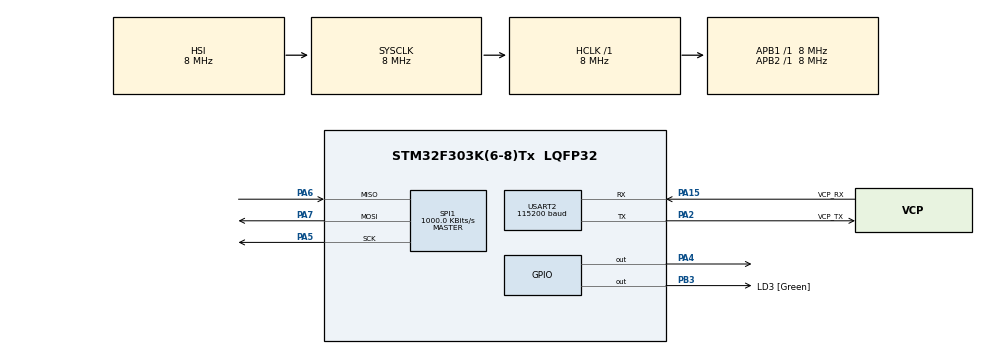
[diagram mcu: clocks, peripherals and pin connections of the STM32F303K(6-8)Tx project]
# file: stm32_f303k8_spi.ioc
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Mcu.Family=STM32F3
Mcu.Name=STM32F303K(6-8)Tx
Mcu.Package=LQFP32
NVIC.PriorityGroup=NVIC_PRIORITYGROUP_4
PA13.GPIO_Label=SWDIO
PA13.Mode=Serial_Wire
PA13.Signal=SYS_JTMS-SWDIO
PA14.GPIO_Label=SWCLK
PA14.Mode=Serial_Wire
PA14.Signal=SYS_JTCK-SWCLK
PA15.GPIO_Label=VCP_RX
PA15.Mode=Asynchronous
PA15.Signal=USART2_RX
PA2.GPIO_Label=VCP_TX
PA2.Mode=Asynchronous
PA2.Signal=USART2_TX
PA4.GPIO_PuPd=GPIO_NOPULL
PA4.Signal=GPIO_Output
PA5.GPIO_PuPd=GPIO_PULLUP
PA5.Mode=Full_Duplex_Master
PA5.Signal=SPI1_SCK
PA6.GPIO_PuPd=GPIO_PULLUP
PA6.Mode=Full_Duplex_Master
PA6.Signal=SPI1_MISO
PA7.GPIO_PuPd=GPIO_PULLUP
PA7.Mode=Full_Duplex_Master
PA7.Signal=SPI1_MOSI
PB3.GPIO_Label=LD3 [Green]
PB3.Signal=GPIO_Output
PF0\ /\ OSC_IN.GPIO_Label=MCO
PF0\ /\ OSC_IN.Mode=HSE-External-Clock-Source
PF0\ /\ OSC_IN.Signal=RCC_OSC_IN
ProjectManager.HeapSize=0x200
ProjectManager.StackSize=0x400
ProjectManager.TargetToolchain=STM32CubeIDE
RCC.AHBFreq_Value=8000000
RCC.APB1Freq_Value=8000000
RCC.APB1TimFreq_Value=8000000
RCC.APB2Freq_Value=8000000
RCC.APB2TimFreq_Value=8000000
RCC.CortexFreq_Value=8000000
RCC.HCLKFreq_Value=8000000
RCC.HSE_VALUE=8000000
RCC.HSI_VALUE=8000000
RCC.PLLMUL=RCC_PLL_MUL9
RCC.SYSCLKFreq_VALUE=8000000
SPI1.BaudRatePrescaler=SPI_BAUDRATEPRESCALER_8
SPI1.CLKPhase=SPI_PHASE_2EDGE
SPI1.CRCCalculation=SPI_CRCCALCULATION_DISABLE
SPI1.CalculateBaudRate=1000.0 KBits/s
SPI1.DataSize=SPI_DATASIZE_8BIT
SPI1.Direction=SPI_DIRECTION_2LINES
SPI1.Mode=SPI_MODE_MASTER
SPI1.VirtualType=VM_MASTER
USART2.BaudRate=115200
USART2.VirtualMode-Asynchronous=VM_ASYNC
board=NUCLEO-F303K8

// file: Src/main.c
/* USER CODE BEGIN Header */
/**
  ******************************************************************************
  * @file           : main.c
  * @brief          : Main program body
  ******************************************************************************
  * @attention
  *
  * <h2><center>&copy; Copyright (c) 2019 STMicroelectronics.
  * All rights reserved.</center></h2>
  *
  * This software component is licensed by ST under BSD 3-Clause license,
  * the "License"; You may not use this file except in compliance with the
  * License. You may obtain a copy of the License at:
  *                        opensource.org/licenses/BSD-3-Clause
  *
  ******************************************************************************
  */
/* USER CODE END Header */

#include "main.h"

SPI_HandleTypeDef hspi1;

UART_HandleTypeDef huart2;

void SystemClock_Config(void);
static void MX_GPIO_Init(void);
static void MX_USART2_UART_Init(void);
static void MX_SPI1_Init(void);

int main(void)
{

  /* MCU Configuration--------------------------------------------------------*/

  /* Reset of all peripherals, Initializes the Flash interface and the Systick. */
  HAL_Init();

  /* Configure the system clock */
  SystemClock_Config();

  /* Initialize all configured peripherals */
  MX_GPIO_Init();
  MX_USART2_UART_Init();
  MX_SPI1_Init();
  /* USER CODE BEGIN 2 */
  uint8_t aTxBuffer[]={"ababababab"};
  aTxBuffer[0]=0xA;
  uint8_t aTxBuffer2[]={"jajajajaja"};
  uint8_t aRxBuffer[11]={0};
  uint8_t aRxBuffer2[11]={0};
  HAL_GPIO_WritePin(GPIOA,GPIO_PIN_4,1);
  /* USER CODE END 2 */

  /* Infinite loop */
  while (1)
  {

    /* USER CODE BEGIN 3 */
	HAL_GPIO_WritePin(GPIOA,GPIO_PIN_4,0);
	for(int i = 0; i < 11; i++){

		HAL_SPI_TransmitReceive(&hspi1,(uint8_t*)&aTxBuffer[i],(uint8_t*)&aRxBuffer[i],1,0xFFFFFFFF);

	}
	HAL_GPIO_WritePin(GPIOA,GPIO_PIN_4,1);
	HAL_UART_Transmit(&huart2,aRxBuffer,11,0xFF);
	HAL_Delay(100);

  }
  /* USER CODE END 3 */
}

void SystemClock_Config(void)
{
  RCC_OscInitTypeDef RCC_OscInitStruct = {0};
  RCC_ClkInitTypeDef RCC_ClkInitStruct = {0};

  /** Initializes the CPU, AHB and APB busses clocks
  */
  RCC_OscInitStruct.OscillatorType = RCC_OSCILLATORTYPE_HSI;
  RCC_OscInitStruct.HSIState = RCC_HSI_ON;
  RCC_OscInitStruct.HSICalibrationValue = RCC_HSICALIBRATION_DEFAULT;
  RCC_OscInitStruct.PLL.PLLState = RCC_PLL_NONE;
  if (HAL_RCC_OscConfig(&RCC_OscInitStruct) != HAL_OK)
  {
    Error_Handler();
  }
  /** Initializes the CPU, AHB and APB busses clocks
  */
  RCC_ClkInitStruct.ClockType = RCC_CLOCKTYPE_HCLK|RCC_CLOCKTYPE_SYSCLK
                              |RCC_CLOCKTYPE_PCLK1|RCC_CLOCKTYPE_PCLK2;
  RCC_ClkInitStruct.SYSCLKSource = RCC_SYSCLKSOURCE_HSI;
  RCC_ClkInitStruct.AHBCLKDivider = RCC_SYSCLK_DIV1;
  RCC_ClkInitStruct.APB1CLKDivider = RCC_HCLK_DIV1;
  RCC_ClkInitStruct.APB2CLKDivider = RCC_HCLK_DIV1;

  if (HAL_RCC_ClockConfig(&RCC_ClkInitStruct, FLASH_LATENCY_0) != HAL_OK)
  {
    Error_Handler();
  }
}

static void MX_SPI1_Init(void)
{

  /* SPI1 parameter configuration*/
  hspi1.Instance = SPI1;
  hspi1.Init.Mode = SPI_MODE_MASTER;
  hspi1.Init.Direction = SPI_DIRECTION_2LINES;
  hspi1.Init.DataSize = SPI_DATASIZE_8BIT;
  hspi1.Init.CLKPolarity = SPI_POLARITY_LOW;
  hspi1.Init.CLKPhase = SPI_PHASE_2EDGE;
  hspi1.Init.NSS = SPI_NSS_SOFT;
  hspi1.Init.BaudRatePrescaler = SPI_BAUDRATEPRESCALER_8;
  hspi1.Init.FirstBit = SPI_FIRSTBIT_MSB;
  hspi1.Init.TIMode = SPI_TIMODE_DISABLE;
  hspi1.Init.CRCCalculation = SPI_CRCCALCULATION_DISABLE;
  hspi1.Init.CRCPolynomial = 7;
  hspi1.Init.CRCLength = SPI_CRC_LENGTH_DATASIZE;
  hspi1.Init.NSSPMode = SPI_NSS_PULSE_DISABLE;
  if (HAL_SPI_Init(&hspi1) != HAL_OK)
  {
    Error_Handler();
  }

}

static void MX_USART2_UART_Init(void)
{

  huart2.Instance = USART2;
  huart2.Init.BaudRate = 115200;
  huart2.Init.WordLength = UART_WORDLENGTH_8B;
  huart2.Init.StopBits = UART_STOPBITS_1;
  huart2.Init.Parity = UART_PARITY_NONE;
  huart2.Init.Mode = UART_MODE_TX_RX;
  huart2.Init.HwFlowCtl = UART_HWCONTROL_NONE;
  huart2.Init.OverSampling = UART_OVERSAMPLING_16;
  huart2.Init.OneBitSampling = UART_ONE_BIT_SAMPLE_DISABLE;
  huart2.AdvancedInit.AdvFeatureInit = UART_ADVFEATURE_NO_INIT;
  if (HAL_UART_Init(&huart2) != HAL_OK)
  {
    Error_Handler();
  }

}

static void MX_GPIO_Init(void)
{
  GPIO_InitTypeDef GPIO_InitStruct = {0};

  /* GPIO Ports Clock Enable */
  __HAL_RCC_GPIOF_CLK_ENABLE();
  __HAL_RCC_GPIOA_CLK_ENABLE();
  __HAL_RCC_GPIOB_CLK_ENABLE();

  /*Configure GPIO pin Output Level */
  HAL_GPIO_WritePin(GPIOA, GPIO_PIN_4, GPIO_PIN_RESET);

  /*Configure GPIO pin Output Level */
  HAL_GPIO_WritePin(LD3_GPIO_Port, LD3_Pin, GPIO_PIN_RESET);

  /*Configure GPIO pin : PA4 */
  GPIO_InitStruct.Pin = GPIO_PIN_4;
  GPIO_InitStruct.Mode = GPIO_MODE_OUTPUT_PP;
  GPIO_InitStruct.Pull = GPIO_NOPULL;
  GPIO_InitStruct.Speed = GPIO_SPEED_FREQ_LOW;
  HAL_GPIO_Init(GPIOA, &GPIO_InitStruct);

  /*Configure GPIO pin : LD3_Pin */
  GPIO_InitStruct.Pin = LD3_Pin;
  GPIO_InitStruct.Mode = GPIO_MODE_OUTPUT_PP;
  GPIO_InitStruct.Pull = GPIO_NOPULL;
  GPIO_InitStruct.Speed = GPIO_SPEED_FREQ_LOW;
  HAL_GPIO_Init(LD3_GPIO_Port, &GPIO_InitStruct);

}

void Error_Handler(void)
{
}

/************************ (C) COPYRIGHT STMicroelectronics *****END OF FILE****/
